# nrf52840 register map
Vendor: Nordic Semiconductor; Series: nrf52; File version: 1
CPU: CM4 r0p1, little endian, MPU, FPU, 3 interrupt priority bits
Registers are 32-bit, read-write, reset 0x0 unless marked. A register's access mark holds for its fields unless they carry their own. Offsets are from the block's base; [hi:lo] are bit positions; lines under a group give offsets from that group; {n}, {i} and the like mark numbered series.

## PPI — Programmable Peripheral Interconnect
Base 0x4001F000
{0x0+8i} TASKS_CHG[{i}] (i=0..5) group — Channel group tasks
  0x00 EN wo — Description cluster[n]: Enable channel group n
    [0] EN
  0x04 DIS wo — Description cluster[n]: Disable channel group n
    [0] DIS
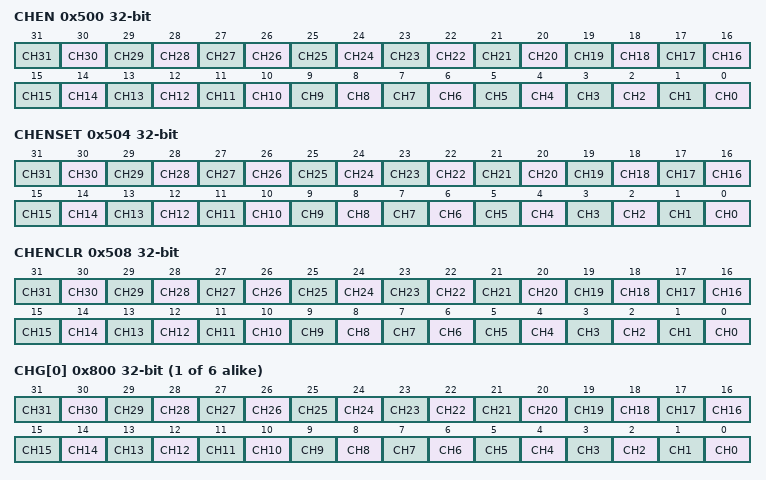
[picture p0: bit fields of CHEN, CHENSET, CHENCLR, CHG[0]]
0x500 CHEN — Channel enable register
  [all] fields
    0=Disabled (Disable channel); 1=Enabled (Enable channel)
  [n] CH{n} (n=0..31) — Enable or disable channel {n}
0x504 CHENSET write-1-sets — Channel enable set register
  [all] fields
    on read: 0=Disabled (Read: channel disabled); 1=Enabled (Read: channel enabled) | on write: 1=Set (Write: Enable channel)
  [n] CH{n} (n=0..31) — Channel {n} enable set register. Writing '0' has no effect
0x508 CHENCLR write-1-clears — Channel enable clear register
  [all] fields
    on read: 0=Disabled (Read: channel disabled); 1=Enabled (Read: channel enabled) | on write: 1=Clear (Write: disable channel)
  [n] CH{n} (n=0..31) — Channel {n} enable clear register. Writing '0' has no effect
{0x510+8i} CH[{i}] (i=0..19) group — PPI Channel
  0x00 EEP — Description cluster[n]: Channel n event end-point
    [31:0] EEP — Pointer to event register. Accepts only addresses to registers from the Event group.
  0x04 TEP — Description cluster[n]: Channel n task end-point
    [31:0] TEP — Pointer to task register. Accepts only addresses to registers from the Task group.
{0x800+4i} CHG[{i}] (i=0..5) — Description collection[n]: Channel group n
  [all] fields
    0=Excluded; 1=Included
  [n] CH{n} (n=0..31) — Include or exclude channel {n}
{0x910+4i} FORK[{i}] (i=0..31) group
  0x00 TEP — Description cluster[n]: Channel n task end-point
    [31:0] TEP — Pointer to task register

## P0 — GPIO Port 1
Base 0x50000000
Same registers: P1 0x50000300 (alternate view of P0)
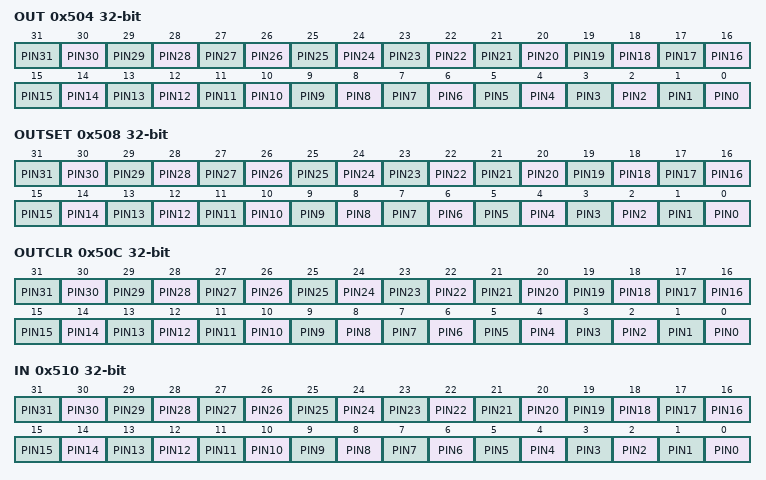
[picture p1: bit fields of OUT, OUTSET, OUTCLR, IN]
0x504 OUT — Write GPIO port
  [all] fields
    0=Low (Pin driver is low); 1=High (Pin driver is high)
  [n] PIN{n} (n=0..31)
0x508 OUTSET write-1-sets — Set individual bits in GPIO port
  [all] fields
    on read: 0=Low (Read: pin driver is low); 1=High (Read: pin driver is high) | on write: 1=Set (Write: writing a '1' sets the pin high; writing a '0' has no effect)
  [n] PIN{n} (n=0..31)
0x50C OUTCLR write-1-clears — Clear individual bits in GPIO port
  [all] fields
    on read: 0=Low (Read: pin driver is low); 1=High (Read: pin driver is high) | on write: 1=Clear (Write: writing a '1' sets the pin low; writing a '0' has no effect)
  [n] PIN{n} (n=0..31)
0x510 IN ro — Read GPIO port
  [all] fields
    0=Low (Pin input is low); 1=High (Pin input is high)
  [n] PIN{n} (n=0..31)
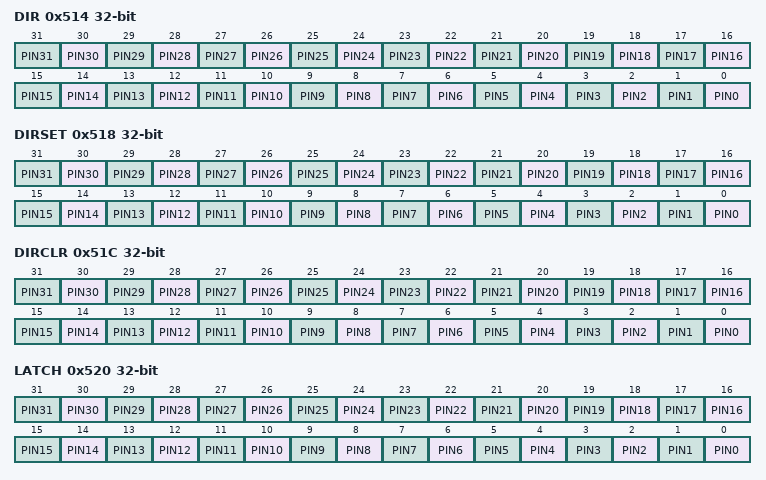
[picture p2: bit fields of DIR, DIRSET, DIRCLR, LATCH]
0x514 DIR — Direction of GPIO pins
  [all] fields
    0=Input (Pin set as input); 1=Output (Pin set as output)
  [n] PIN{n} (n=0..31)
0x518 DIRSET write-1-sets
  [all] fields
    on read: 0=Input (Read: pin set as input); 1=Output (Read: pin set as output) | on write: 1=Set (Write: writing a '1' sets pin to output; writing a '0' has no effect)
  [n] PIN{n} (n=0..31) — Set as output pin {n}
0x51C DIRCLR write-1-clears — DIR clear register
  [all] fields
    on read: 0=Input (Read: pin set as input); 1=Output (Read: pin set as output) | on write: 1=Clear (Write: writing a '1' sets pin to input; writing a '0' has no effect)
  [n] PIN{n} (n=0..31) — Set as input pin {n}
0x520 LATCH — Latch register indicating what GPIO pins that have met the criteria set in the PIN_CNF[n].SENSE registers
  [all] fields
    0=NotLatched (Criteria has not been met); 1=Latched (Criteria has been met)
  [n] PIN{n} (n=0..31) — Status on whether PIN{n} has met criteria set in PIN_CNF{n}.SENSE register. Write '1' to clear.
0x524 DETECTMODE — Select between default DETECT signal behaviour and LDETECT mode
  [0] DETECTMODE
    0=Default (DETECT directly connected to PIN DETECT signals); 1=LDETECT (Use the latched LDETECT behaviour)
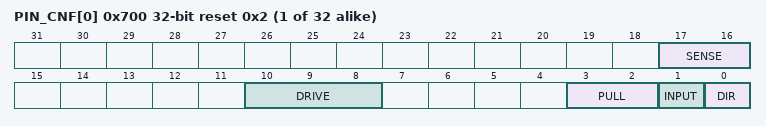
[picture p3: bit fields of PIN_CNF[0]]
{0x700+4i} PIN_CNF[{i}] (i=0..31) reset 0x2 — Description collection[n]: Configuration of GPIO pins
  [17:16] SENSE — Pin sensing mechanism
    0=Disabled; 2=High (Sense for high level); 3=Low (Sense for low level)
  [10:8] DRIVE — Drive configuration
    0=S0S1 (Standard '0', standard '1'); 1=H0S1 (High drive '0', standard '1'); 2=S0H1 (Standard '0', high drive '1'); 3=H0H1 (High drive '0', high 'drive '1''); 4=D0S1 (Disconnect '0' standard '1' (normally used for wired-or connections)); 5=D0H1 (Disconnect '0', high drive '1' (normally used for wired-or connections)); 6=S0D1 (Standard '0'. disconnect '1' (normally used for wired-and connections)); 7=H0D1 (High drive '0', disconnect '1' (normally used for wired-and connections))
  [3:2] PULL — Pull configuration
    0=Disabled (No pull); 1=Pull down on pin; 3=Pull up on pin
  [1] INPUT — Connect or disconnect input buffer
    0=Connect input buffer; 1=Disconnect input buffer
  [0] DIR — Pin direction. Same physical register as DIR register
    0=Input (Configure pin as an input pin); 1=Output (Configure pin as an output pin)

## CC_HOST_RGF — CRYPTOCELL HOST_RGF interface
Base 0x5002A000
0x1A38 HOST_CRYPTOKEY_SEL — AES hardware key select
  [1:0] HOST_CRYPTOKEY_SEL — Select the source of the HW key that is used by the AES engine
    0=K_DR (Use device root key K_DR from CRYPTOCELL AO power domain); 1=K_PRTL (Use hard-coded RTL key K_PRTL); 2=Session (Use provided session key)
0x1A4C HOST_IOT_KPRTL_LOCK — This write-once register is the K_PRTL lock register. When this register is set, K_PRTL can not be used and a zeroed key will be used instead. The value of this register is saved in the CRYPTOCELL AO power domain.
  [0] HOST_IOT_KPRTL_LOCK — This register is the K_PRTL lock register. When this register is set, K_PRTL can not be used and a zeroed key will be used instead. The value of this register is saved in the CRYPTOCELL AO power domain.
    0=Disabled (K_PRTL can be selected for use from register HOST_CRYPTOKEY_SEL); 1=Enabled (K_PRTL has been locked until next power-on reset (POR). If K_PRTL is selected anyway, a zeroed key will be used instead.)
0x1A50 HOST_IOT_KDR0 — This register holds bits 31:0 of K_DR. The value of this register is saved in the CRYPTOCELL AO power domain. Reading from this address returns the K_DR valid status indicating if K_DR is successfully retained.
  [31:0] HOST_IOT_KDR0 — Write: K_DR bits 31:0 Read: 0x00000000 when 128-bit K_DR key value is not yet retained in the CRYPTOCELL AO power domain Read: 0x00000001 when 128-bit K_DR key value is successfully retained in the CRYPTOCELL AO power domain
{0x1A50+4i} HOST_IOT_KDR{i} wo (i=1..3) — This register holds bits {32i+31}:{32i} of K_DR. The value of this register is saved in the CRYPTOCELL AO power domain.
  [31:0] HOST_IOT_KDR{i} — K_DR bits {32i+31}:{32i}
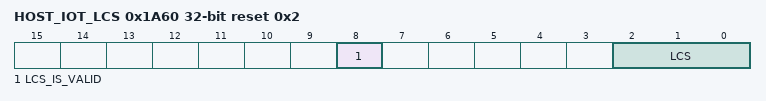
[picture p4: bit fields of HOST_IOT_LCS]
0x1A60 HOST_IOT_LCS reset 0x2 — Controls lifecycle state (LCS) for CRYPTOCELL subsystem
  [8] LCS_IS_VALID — This field is read-only and indicates if CRYPTOCELL LCS has been successfully configured since last reset
    0=Invalid (A valid LCS is not yet retained in the CRYPTOCELL AO power domain); 1=Valid (A valid LCS is successfully retained in the CRYPTOCELL AO power domain)
  [2:0] LCS — Lifecycle state value. This field is write-once per reset.
    0=Debug (CC310 operates in debug mode); 2=Secure (CC310 operates in secure mode)

## CRYPTOCELL — ARM TrustZone CryptoCell register interface
Base 0x5002A000; alternate view of CC_HOST_RGF
0x500 ENABLE — Enable CRYPTOCELL subsystem
  [0] ENABLE — Enable or disable the CRYPTOCELL subsystem
    0=Disabled (CRYPTOCELL subsystem disabled); 1=Enabled (CRYPTOCELL subsystem enabled)
